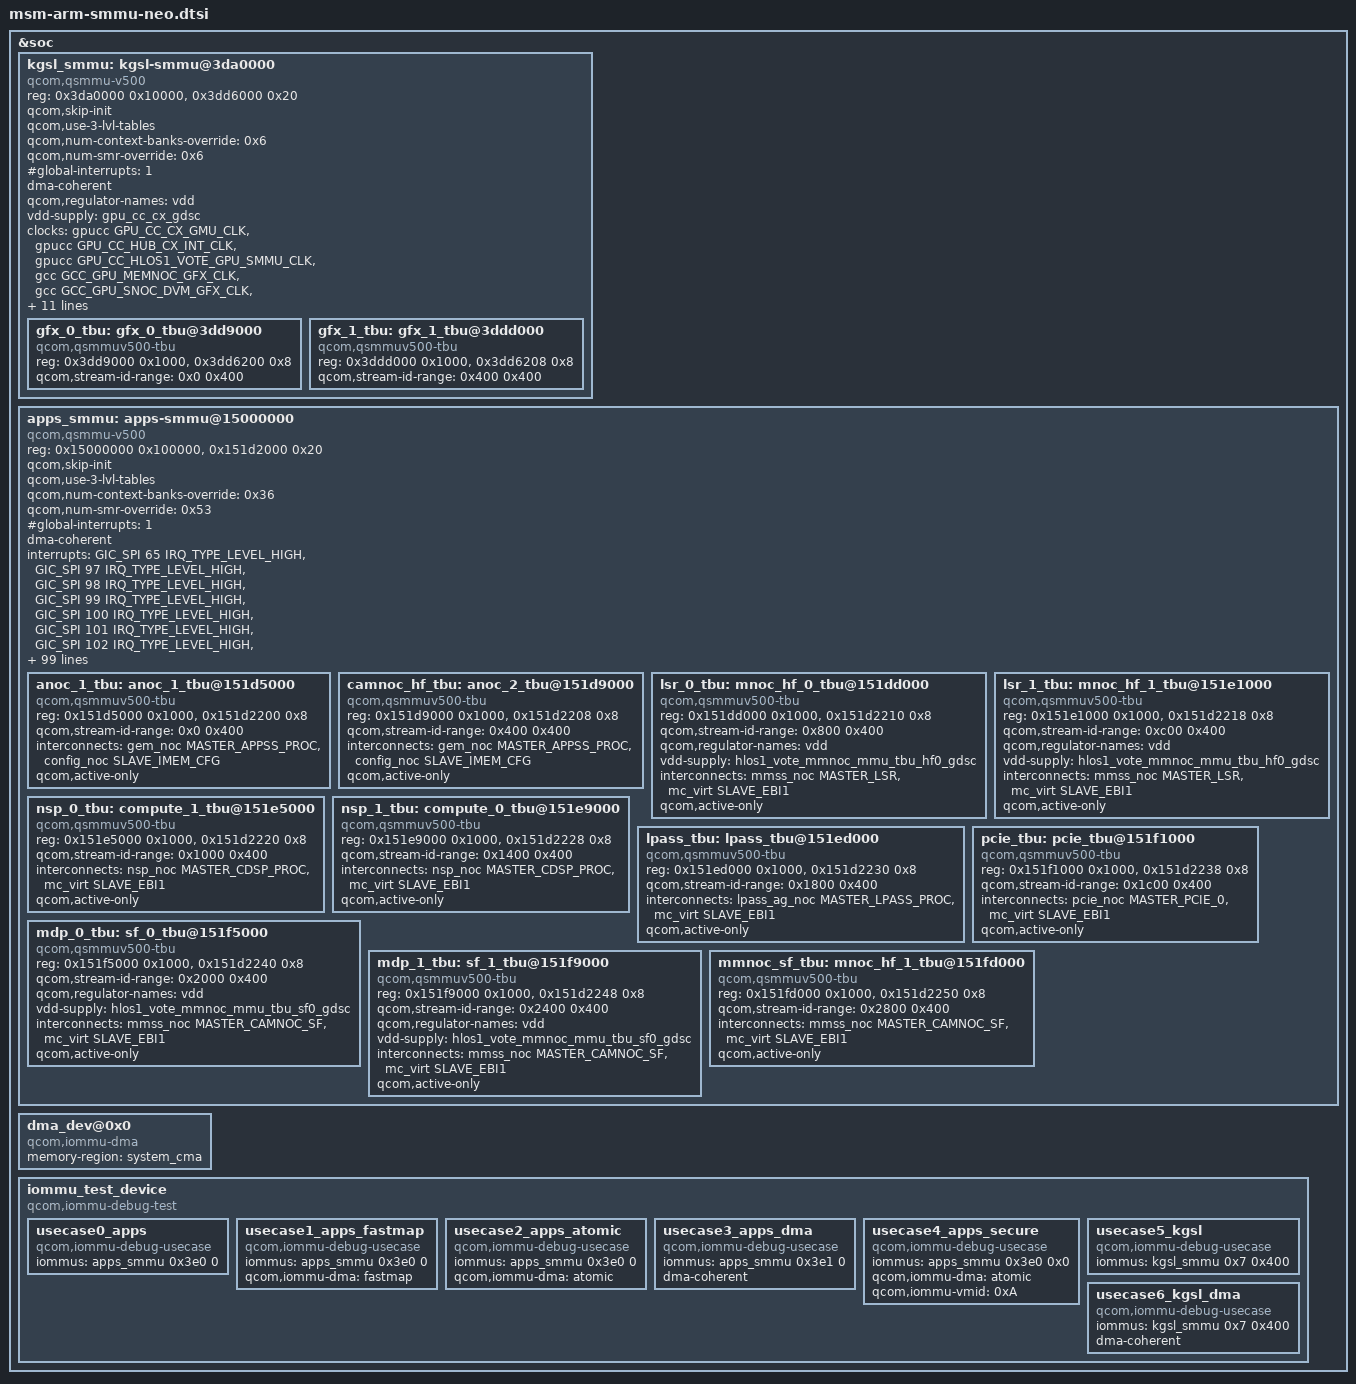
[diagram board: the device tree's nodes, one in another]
#include <dt-bindings/interrupt-controller/arm-gic.h>

&soc {
	kgsl_smmu: kgsl-smmu@3da0000 {
		compatible = "qcom,qsmmu-v500", "qcom,adreno-smmu";
		reg = <0x3da0000 0x10000>,
			<0x3dd6000 0x20>;
		reg-names = "base", "tcu-base";
		#iommu-cells = <2>;
		qcom,skip-init;
		qcom,use-3-lvl-tables;
		qcom,num-context-banks-override = <0x6>;
		qcom,num-smr-override = <0x6>;
		#global-interrupts = <1>;
		#size-cells = <1>;
		#address-cells = <1>;
		ranges;
		dma-coherent;

		qcom,regulator-names = "vdd";
		vdd-supply = <&gpu_cc_cx_gdsc>;

		clocks = <&gpucc GPU_CC_CX_GMU_CLK>,
			 <&gpucc GPU_CC_HUB_CX_INT_CLK>,
			 <&gpucc GPU_CC_HLOS1_VOTE_GPU_SMMU_CLK>,
			 <&gcc GCC_GPU_MEMNOC_GFX_CLK>,
			 <&gcc GCC_GPU_SNOC_DVM_GFX_CLK>,
			 <&gpucc GPU_CC_AHB_CLK>;
		clock-names =
			"gpu_cc_cx_gmu",
			"gpu_cc_hub_cx_int",
			"gpu_cc_hlos1_vote_gpu_smmu",
			"gcc_gpu_memnoc_gfx",
			"gcc_gpu_snoc_dvm_gfx",
			"gpu_cc_ahb";

		qcom,actlr =
			/* All CBs of GFX: +15 deep PF */
			<0x000 0x7ff 0x32B>;

		interrupts =	<GIC_SPI 673 IRQ_TYPE_LEVEL_HIGH>,
				<GIC_SPI 678 IRQ_TYPE_LEVEL_HIGH>,
				<GIC_SPI 679 IRQ_TYPE_LEVEL_HIGH>,
				<GIC_SPI 680 IRQ_TYPE_LEVEL_HIGH>,
				<GIC_SPI 681 IRQ_TYPE_LEVEL_HIGH>,
				<GIC_SPI 682 IRQ_TYPE_LEVEL_HIGH>,
				<GIC_SPI 683 IRQ_TYPE_LEVEL_HIGH>,
				<GIC_SPI 684 IRQ_TYPE_LEVEL_HIGH>,
				<GIC_SPI 685 IRQ_TYPE_LEVEL_HIGH>;

		gfx_0_tbu: gfx_0_tbu@3dd9000 {
			compatible = "qcom,qsmmuv500-tbu";
			reg = <0x3dd9000 0x1000>,
				<0x3dd6200 0x8>;
			reg-names = "base", "status-reg";
			qcom,stream-id-range = <0x0 0x400>;
		};

		gfx_1_tbu: gfx_1_tbu@3ddd000 {
			compatible = "qcom,qsmmuv500-tbu";
			reg = <0x3ddd000 0x1000>,
				<0x3dd6208 0x8>;
			reg-names = "base", "status-reg";
			qcom,stream-id-range = <0x400 0x400>;
		};
	};

	apps_smmu: apps-smmu@15000000 {
		compatible = "qcom,qsmmu-v500";
		reg = <0x15000000 0x100000>,
			<0x151d2000 0x20>;
		reg-names = "base", "tcu-base";
		#iommu-cells = <2>;
		qcom,skip-init;
		qcom,use-3-lvl-tables;
		qcom,num-context-banks-override = <0x36>;
		qcom,num-smr-override = <0x53>;
		#global-interrupts = <1>;
		#size-cells = <1>;
		#address-cells = <1>;
		ranges;
		dma-coherent;
		interrupts =	<GIC_SPI 65 IRQ_TYPE_LEVEL_HIGH>,
				<GIC_SPI 97 IRQ_TYPE_LEVEL_HIGH>,
				<GIC_SPI 98 IRQ_TYPE_LEVEL_HIGH>,
				<GIC_SPI 99 IRQ_TYPE_LEVEL_HIGH>,
				<GIC_SPI 100 IRQ_TYPE_LEVEL_HIGH>,
				<GIC_SPI 101 IRQ_TYPE_LEVEL_HIGH>,
				<GIC_SPI 102 IRQ_TYPE_LEVEL_HIGH>,
				<GIC_SPI 103 IRQ_TYPE_LEVEL_HIGH>,
				<GIC_SPI 104 IRQ_TYPE_LEVEL_HIGH>,
				<GIC_SPI 105 IRQ_TYPE_LEVEL_HIGH>,
				<GIC_SPI 106 IRQ_TYPE_LEVEL_HIGH>,
				<GIC_SPI 107 IRQ_TYPE_LEVEL_HIGH>,
				<GIC_SPI 108 IRQ_TYPE_LEVEL_HIGH>,
				<GIC_SPI 109 IRQ_TYPE_LEVEL_HIGH>,
				<GIC_SPI 110 IRQ_TYPE_LEVEL_HIGH>,
				<GIC_SPI 111 IRQ_TYPE_LEVEL_HIGH>,
				<GIC_SPI 112 IRQ_TYPE_LEVEL_HIGH>,
				<GIC_SPI 113 IRQ_TYPE_LEVEL_HIGH>,
				<GIC_SPI 114 IRQ_TYPE_LEVEL_HIGH>,
				<GIC_SPI 115 IRQ_TYPE_LEVEL_HIGH>,
				<GIC_SPI 116 IRQ_TYPE_LEVEL_HIGH>,
				<GIC_SPI 117 IRQ_TYPE_LEVEL_HIGH>,
				<GIC_SPI 118 IRQ_TYPE_LEVEL_HIGH>,
				<GIC_SPI 181 IRQ_TYPE_LEVEL_HIGH>,
				<GIC_SPI 182 IRQ_TYPE_LEVEL_HIGH>,
				<GIC_SPI 183 IRQ_TYPE_LEVEL_HIGH>,
				<GIC_SPI 184 IRQ_TYPE_LEVEL_HIGH>,
				<GIC_SPI 185 IRQ_TYPE_LEVEL_HIGH>,
				<GIC_SPI 186 IRQ_TYPE_LEVEL_HIGH>,
				<GIC_SPI 187 IRQ_TYPE_LEVEL_HIGH>,
				<GIC_SPI 188 IRQ_TYPE_LEVEL_HIGH>,
				<GIC_SPI 189 IRQ_TYPE_LEVEL_HIGH>,
				<GIC_SPI 190 IRQ_TYPE_LEVEL_HIGH>,
				<GIC_SPI 191 IRQ_TYPE_LEVEL_HIGH>,
				<GIC_SPI 192 IRQ_TYPE_LEVEL_HIGH>,
				<GIC_SPI 315 IRQ_TYPE_LEVEL_HIGH>,
				<GIC_SPI 316 IRQ_TYPE_LEVEL_HIGH>,
				<GIC_SPI 317 IRQ_TYPE_LEVEL_HIGH>,
				<GIC_SPI 318 IRQ_TYPE_LEVEL_HIGH>,
				<GIC_SPI 319 IRQ_TYPE_LEVEL_HIGH>,
				<GIC_SPI 320 IRQ_TYPE_LEVEL_HIGH>,
				<GIC_SPI 321 IRQ_TYPE_LEVEL_HIGH>,
				<GIC_SPI 322 IRQ_TYPE_LEVEL_HIGH>,
				<GIC_SPI 323 IRQ_TYPE_LEVEL_HIGH>,
				<GIC_SPI 324 IRQ_TYPE_LEVEL_HIGH>,
				<GIC_SPI 325 IRQ_TYPE_LEVEL_HIGH>,
				<GIC_SPI 326 IRQ_TYPE_LEVEL_HIGH>,
				<GIC_SPI 327 IRQ_TYPE_LEVEL_HIGH>,
				<GIC_SPI 328 IRQ_TYPE_LEVEL_HIGH>,
				<GIC_SPI 329 IRQ_TYPE_LEVEL_HIGH>,
				<GIC_SPI 330 IRQ_TYPE_LEVEL_HIGH>,
				<GIC_SPI 331 IRQ_TYPE_LEVEL_HIGH>,
				<GIC_SPI 332 IRQ_TYPE_LEVEL_HIGH>,
				<GIC_SPI 333 IRQ_TYPE_LEVEL_HIGH>,
				<GIC_SPI 334 IRQ_TYPE_LEVEL_HIGH>,
				<GIC_SPI 335 IRQ_TYPE_LEVEL_HIGH>,
				<GIC_SPI 336 IRQ_TYPE_LEVEL_HIGH>,
				<GIC_SPI 337 IRQ_TYPE_LEVEL_HIGH>,
				<GIC_SPI 338 IRQ_TYPE_LEVEL_HIGH>,
				<GIC_SPI 339 IRQ_TYPE_LEVEL_HIGH>,
				<GIC_SPI 340 IRQ_TYPE_LEVEL_HIGH>,
				<GIC_SPI 341 IRQ_TYPE_LEVEL_HIGH>,
				<GIC_SPI 342 IRQ_TYPE_LEVEL_HIGH>,
				<GIC_SPI 343 IRQ_TYPE_LEVEL_HIGH>,
				<GIC_SPI 344 IRQ_TYPE_LEVEL_HIGH>,
				<GIC_SPI 345 IRQ_TYPE_LEVEL_HIGH>,
				<GIC_SPI 395 IRQ_TYPE_LEVEL_HIGH>,
				<GIC_SPI 396 IRQ_TYPE_LEVEL_HIGH>,
				<GIC_SPI 397 IRQ_TYPE_LEVEL_HIGH>,
				<GIC_SPI 398 IRQ_TYPE_LEVEL_HIGH>,
				<GIC_SPI 399 IRQ_TYPE_LEVEL_HIGH>,
				<GIC_SPI 400 IRQ_TYPE_LEVEL_HIGH>,
				<GIC_SPI 401 IRQ_TYPE_LEVEL_HIGH>,
				<GIC_SPI 402 IRQ_TYPE_LEVEL_HIGH>,
				<GIC_SPI 403 IRQ_TYPE_LEVEL_HIGH>,
				<GIC_SPI 404 IRQ_TYPE_LEVEL_HIGH>,
				<GIC_SPI 405 IRQ_TYPE_LEVEL_HIGH>,
				<GIC_SPI 406 IRQ_TYPE_LEVEL_HIGH>,
				<GIC_SPI 407 IRQ_TYPE_LEVEL_HIGH>,
				<GIC_SPI 408 IRQ_TYPE_LEVEL_HIGH>,
				<GIC_SPI 409 IRQ_TYPE_LEVEL_HIGH>,
				<GIC_SPI 418 IRQ_TYPE_LEVEL_HIGH>,
				<GIC_SPI 419 IRQ_TYPE_LEVEL_HIGH>,
				<GIC_SPI 412 IRQ_TYPE_LEVEL_HIGH>,
				<GIC_SPI 421 IRQ_TYPE_LEVEL_HIGH>,
				<GIC_SPI 707 IRQ_TYPE_LEVEL_HIGH>,
				<GIC_SPI 423 IRQ_TYPE_LEVEL_HIGH>,
				<GIC_SPI 424 IRQ_TYPE_LEVEL_HIGH>,
				<GIC_SPI 425 IRQ_TYPE_LEVEL_HIGH>,
				<GIC_SPI 690 IRQ_TYPE_LEVEL_HIGH>,
				<GIC_SPI 691 IRQ_TYPE_LEVEL_HIGH>,
				<GIC_SPI 692 IRQ_TYPE_LEVEL_HIGH>,
				<GIC_SPI 693 IRQ_TYPE_LEVEL_HIGH>,
				<GIC_SPI 694 IRQ_TYPE_LEVEL_HIGH>,
				<GIC_SPI 695 IRQ_TYPE_LEVEL_HIGH>,
				<GIC_SPI 696 IRQ_TYPE_LEVEL_HIGH>,
				<GIC_SPI 697 IRQ_TYPE_LEVEL_HIGH>;

		qcom,actlr =
			/* For display, camera +0 deep PF */
			<0x400 0x3ff 0x001>,
			<0x2000 0x3ff 0x001>,
			<0x2400 0x3ff 0x001>,
			<0x2800 0xff 0x001>,
			<0x2900 0x21 0x001>,
			<0x2902 0x0 0x001>,

			/* For video +3 deep PF */
			<0x2980 0x7 0x103>,
			<0x29c0 0x6 0x103>,

			/* For compute +15 deep PF */
			<0x1000 0x3ff 0x303>,
			<0x1400 0x3ff 0x303>;

		interconnects = <&gem_noc MASTER_APPSS_PROC
				&config_noc SLAVE_TCU>;
		qcom,active-only;

		anoc_1_tbu: anoc_1_tbu@151d5000 {
			compatible = "qcom,qsmmuv500-tbu";
			reg = <0x151d5000 0x1000>,
				<0x151d2200 0x8>;
			reg-names = "base", "status-reg";
			qcom,stream-id-range = <0x0 0x400>;
			interconnects = <&gem_noc MASTER_APPSS_PROC
					&config_noc SLAVE_IMEM_CFG>;
			qcom,active-only;
		};

		camnoc_hf_tbu: anoc_2_tbu@151d9000 {
			compatible = "qcom,qsmmuv500-tbu";
			reg = <0x151d9000 0x1000>,
				<0x151d2208  0x8>;
			reg-names = "base", "status-reg";
			qcom,stream-id-range = <0x400 0x400>;
			interconnects = <&gem_noc MASTER_APPSS_PROC
					&config_noc SLAVE_IMEM_CFG>;
			qcom,active-only;
		};

		lsr_0_tbu: mnoc_hf_0_tbu@151dd000 {
			compatible = "qcom,qsmmuv500-tbu";
			reg = <0x151dd000 0x1000>,
				<0x151d2210 0x8>;
			reg-names = "base", "status-reg";
			qcom,stream-id-range = <0x800 0x400>;
			qcom,regulator-names = "vdd";
			vdd-supply = <&hlos1_vote_mmnoc_mmu_tbu_hf0_gdsc>;
			interconnects = <&mmss_noc MASTER_LSR
					&mc_virt SLAVE_EBI1>;
			qcom,active-only;
		};

		lsr_1_tbu: mnoc_hf_1_tbu@151e1000 {
			compatible = "qcom,qsmmuv500-tbu";
			reg = <0x151e1000 0x1000>,
				<0x151d2218 0x8>;
			reg-names = "base", "status-reg";
			qcom,stream-id-range = <0xc00 0x400>;
			qcom,regulator-names = "vdd";
			vdd-supply = <&hlos1_vote_mmnoc_mmu_tbu_hf0_gdsc>;
			interconnects = <&mmss_noc MASTER_LSR
					&mc_virt SLAVE_EBI1>;
			qcom,active-only;
		};

		nsp_0_tbu: compute_1_tbu@151e5000 {
			compatible = "qcom,qsmmuv500-tbu";
			reg = <0x151e5000 0x1000>,
				<0x151d2220 0x8>;
			reg-names = "base", "status-reg";
			qcom,stream-id-range = <0x1000 0x400>;
			interconnects = <&nsp_noc MASTER_CDSP_PROC
					&mc_virt SLAVE_EBI1>;
			qcom,active-only;
		};

		nsp_1_tbu: compute_0_tbu@151e9000 {
			compatible = "qcom,qsmmuv500-tbu";
			reg = <0x151e9000 0x1000>,
				<0x151d2228 0x8>;
			reg-names = "base", "status-reg";
			qcom,stream-id-range = <0x1400 0x400>;
			interconnects = <&nsp_noc MASTER_CDSP_PROC
					&mc_virt SLAVE_EBI1>;
			qcom,active-only;
		};

		lpass_tbu: lpass_tbu@151ed000 {
			compatible = "qcom,qsmmuv500-tbu";
			reg = <0x151ed000 0x1000>,
				<0x151d2230 0x8>;
			reg-names = "base", "status-reg";
			qcom,stream-id-range = <0x1800 0x400>;
			interconnects = <&lpass_ag_noc MASTER_LPASS_PROC
					&mc_virt SLAVE_EBI1>;
			qcom,active-only;
		};

		pcie_tbu: pcie_tbu@151f1000 {
			compatible = "qcom,qsmmuv500-tbu";
			reg = <0x151f1000 0x1000>,
				<0x151d2238 0x8>;
			reg-names = "base", "status-reg";
			qcom,stream-id-range = <0x1c00 0x400>;
			interconnects = <&pcie_noc MASTER_PCIE_0
					&mc_virt SLAVE_EBI1>;
			qcom,active-only;
		};

		mdp_0_tbu: sf_0_tbu@151f5000 {
			compatible = "qcom,qsmmuv500-tbu";
			reg = <0x151f5000 0x1000>,
				<0x151d2240 0x8>;
			reg-names = "base", "status-reg";
			qcom,stream-id-range = <0x2000 0x400>;
			qcom,regulator-names = "vdd";
			vdd-supply = <&hlos1_vote_mmnoc_mmu_tbu_sf0_gdsc>;
			interconnects = <&mmss_noc MASTER_CAMNOC_SF
					&mc_virt SLAVE_EBI1>;
			qcom,active-only;
		};

		mdp_1_tbu: sf_1_tbu@151f9000 {
			compatible = "qcom,qsmmuv500-tbu";
			reg = <0x151f9000 0x1000>,
				<0x151d2248 0x8>;
			reg-names = "base", "status-reg";
			qcom,stream-id-range = <0x2400 0x400>;
			qcom,regulator-names = "vdd";
			vdd-supply = <&hlos1_vote_mmnoc_mmu_tbu_sf0_gdsc>;
			interconnects = <&mmss_noc MASTER_CAMNOC_SF
					&mc_virt SLAVE_EBI1>;
			qcom,active-only;
		};

		mmnoc_sf_tbu: mnoc_hf_1_tbu@151fd000 {
			compatible = "qcom,qsmmuv500-tbu";
			reg = <0x151fd000 0x1000>,
				<0x151d2250 0x8>;
			reg-names = "base", "status-reg";
			qcom,stream-id-range = <0x2800 0x400>;
			interconnects = <&mmss_noc MASTER_CAMNOC_SF
					&mc_virt SLAVE_EBI1>;
			qcom,active-only;
		};
	};

	dma_dev@0x0 {
		compatible = "qcom,iommu-dma";
		memory-region = <&system_cma>;
	};

	iommu_test_device {
		compatible = "qcom,iommu-debug-test";

		usecase0_apps {
			compatible = "qcom,iommu-debug-usecase";
			iommus = <&apps_smmu 0x3e0 0>;
		};

		usecase1_apps_fastmap {
			compatible = "qcom,iommu-debug-usecase";
			iommus = <&apps_smmu 0x3e0 0>;
			qcom,iommu-dma = "fastmap";
		};

		usecase2_apps_atomic {
			compatible = "qcom,iommu-debug-usecase";
			iommus = <&apps_smmu 0x3e0 0>;
			qcom,iommu-dma = "atomic";
		};

		usecase3_apps_dma {
			compatible = "qcom,iommu-debug-usecase";
			iommus = <&apps_smmu 0x3e1 0>;
			dma-coherent;
		};

		usecase4_apps_secure {
			compatible = "qcom,iommu-debug-usecase";
			iommus = <&apps_smmu 0x3e0 0x0>;
			qcom,iommu-dma = "atomic";
			qcom,iommu-vmid = <0xA>; /* VMID_CP_PIXEL */
		};

		usecase5_kgsl {
			compatible = "qcom,iommu-debug-usecase";
			iommus = <&kgsl_smmu 0x7 0x400>;
		};

		usecase6_kgsl_dma {
			compatible = "qcom,iommu-debug-usecase";
			iommus = <&kgsl_smmu 0x7 0x400>;
			dma-coherent;
		};
	};
};
